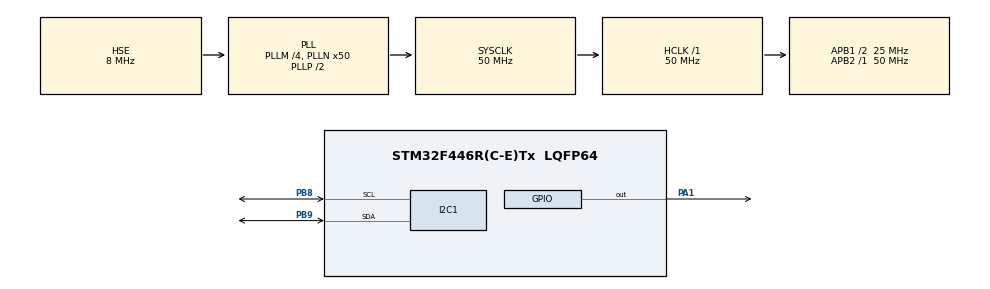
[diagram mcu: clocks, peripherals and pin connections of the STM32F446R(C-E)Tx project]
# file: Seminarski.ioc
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Mcu.Family=STM32F4
Mcu.Name=STM32F446R(C-E)Tx
Mcu.Package=LQFP64
NVIC.PriorityGroup=NVIC_PRIORITYGROUP_4
PA1.Signal=GPIO_Output
PA13.Mode=Serial_Wire
PA13.Signal=SYS_JTMS-SWDIO
PA14.Mode=Serial_Wire
PA14.Signal=SYS_JTCK-SWCLK
PB8.Mode=I2C
PB8.Signal=I2C1_SCL
PB9.Mode=I2C
PB9.Signal=I2C1_SDA
PH0-OSC_IN.Mode=HSE-External-Oscillator
PH0-OSC_IN.Signal=RCC_OSC_IN
PH1-OSC_OUT.Mode=HSE-External-Oscillator
PH1-OSC_OUT.Signal=RCC_OSC_OUT
ProjectManager.HeapSize=0x200
ProjectManager.StackSize=0x400
ProjectManager.TargetToolchain=STM32CubeIDE
RCC.AHBFreq_Value=50000000
RCC.APB1CLKDivider=RCC_HCLK_DIV2
RCC.APB1Freq_Value=25000000
RCC.APB1TimFreq_Value=50000000
RCC.APB2Freq_Value=50000000
RCC.APB2TimFreq_Value=50000000
RCC.CortexFreq_Value=50000000
RCC.HCLKFreq_Value=50000000
RCC.HSE_VALUE=8000000
RCC.PLLM=4
RCC.PLLN=50
RCC.PLLSourceVirtual=RCC_PLLSOURCE_HSE
RCC.SYSCLKFreq_VALUE=50000000
RCC.SYSCLKSource=RCC_SYSCLKSOURCE_PLLCLK
RCC.USBFreq_Value=50000000
RCC.VCOOutputFreq_Value=100000000
TIM6.Period=0xffff-1
TIM6.Prescaler=50-1
VP_TIM6_VS_ClockSourceINT.Mode=Enable_Timer
board=custom

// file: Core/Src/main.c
/* USER CODE BEGIN Header */
/**
  ******************************************************************************
  * @file           : main.c
  * @brief          : Main program body
  ******************************************************************************
  * @attention
  *
  * Copyright (c) 2024 STMicroelectronics.
  * All rights reserved.
  *
  * This software is licensed under terms that can be found in the LICENSE file
  * in the root directory of this software component.
  * If no LICENSE file comes with this software, it is provided AS-IS.
  *
  ******************************************************************************
  */
/* USER CODE END Header */
#include "main.h"
#include "i2c.h"
#include "tim.h"
#include "gpio.h"

/* USER CODE BEGIN Includes */
#include "stdio.h"
/* USER CODE END Includes */

void SystemClock_Config(void);

/* USER CODE BEGIN 0 */
void delay (uint16_t time)
{
	/* change your code here for the delay in microseconds */
	__HAL_TIM_SET_COUNTER(&htim6, 0);
	while ((__HAL_TIM_GET_COUNTER(&htim6))<time);
}

void Display_Temp (float Temp)
{
	char str[20] = {0};
	lcd_put_cur(0, 0);

	sprintf (str, "TEMP: %.2f C", Temp);
	lcd_send_string(str);
	lcd_put_cur(1, 0);
	    if (Temp < 20.0)
	    {
	        lcd_send_string("Obuci se!");
	    }
	    else if (Temp >= 20.0 && Temp <= 30.0)
	    {
	        lcd_send_string("Dobar si!");
	    }
	    else
	    {
	        lcd_send_string("Idi na bazene");
	    }
}

uint8_t Temp_byte1, Temp_byte2;
uint16_t SUM, TEMP;

float Temperature;
uint8_t Presence;

void Set_Pin_Output (GPIO_TypeDef *GPIOx, uint16_t GPIO_Pin)
{
	GPIO_InitTypeDef GPIO_InitStruct = {0};
	GPIO_InitStruct.Pin = GPIO_Pin;
	GPIO_InitStruct.Mode = GPIO_MODE_OUTPUT_PP;
	GPIO_InitStruct.Speed = GPIO_SPEED_FREQ_LOW;
	HAL_GPIO_Init(GPIOx, &GPIO_InitStruct);
}

void Set_Pin_Input (GPIO_TypeDef *GPIOx, uint16_t GPIO_Pin)
{
	GPIO_InitTypeDef GPIO_InitStruct = {0};
	GPIO_InitStruct.Pin = GPIO_Pin;
	GPIO_InitStruct.Mode = GPIO_MODE_INPUT;
	GPIO_InitStruct.Pull = GPIO_PULLUP;
	HAL_GPIO_Init(GPIOx, &GPIO_InitStruct);
}

//DHT11 funkcije
#define DHT11_PORT GPIOA
#define DHT11_PIN GPIO_PIN_1

void DHT11_Start (void)
{
	Set_Pin_Output (DHT11_PORT, DHT11_PIN);  // set the pin as output
	HAL_GPIO_WritePin (DHT11_PORT, DHT11_PIN, 0);   // pull the pin low
	delay (18000);   // wait for 18ms
    HAL_GPIO_WritePin (DHT11_PORT, DHT11_PIN, 1);   // pull the pin high
	delay (20);   // wait for 20us
	Set_Pin_Input(DHT11_PORT, DHT11_PIN);    // set as input
}

uint8_t DHT11_Check_Response (void)
{
	uint8_t Response = 0;
	delay (40);
	if (!(HAL_GPIO_ReadPin (DHT11_PORT, DHT11_PIN)))
	{
		delay (80);
		if ((HAL_GPIO_ReadPin (DHT11_PORT, DHT11_PIN))) Response = 1;
		else Response = -1; // 255
	}
	while ((HAL_GPIO_ReadPin (DHT11_PORT, DHT11_PIN)));   // wait for the pin to go low

	return Response;
}

uint8_t DHT11_Read (void)
{
	uint8_t value = 0;
	    for (int i = 0; i < 8; i++)
	    {
	        while (!(HAL_GPIO_ReadPin(DHT11_PORT, DHT11_PIN)));
	        delay(30);
	        if (HAL_GPIO_ReadPin(DHT11_PORT, DHT11_PIN))
	        {
	            value |= (1 << (7 - i));
	        }
	        while (HAL_GPIO_ReadPin(DHT11_PORT, DHT11_PIN));
	    }
	    return value;
}

/* USER CODE END 0 */

int main(void)
{

  /* MCU Configuration--------------------------------------------------------*/

  /* Reset of all peripherals, Initializes the Flash interface and the Systick. */
  HAL_Init();

  /* Configure the system clock */
  SystemClock_Config();

  /* Initialize all configured peripherals */
  MX_GPIO_Init();
  MX_I2C1_Init();
  MX_TIM6_Init();
  /* USER CODE BEGIN 2 */
  HAL_TIM_Base_Start(&htim6);

  lcd_init();
  lcd_send_string("Ucitavanje >>>");
  HAL_Delay(2000);
  lcd_clear ();

  /* USER CODE END 2 */

  /* Infinite loop */
  while (1)
  {

    /* USER CODE BEGIN 3 */
      Display_Temp(Temperature);

	  DHT11_Start();
	  Presence = DHT11_Check_Response();

	  Temp_byte1 = DHT11_Read ();
	  Temp_byte2 = DHT11_Read ();
	  SUM = DHT11_Read();

	  TEMP = Temp_byte1;

	  Temperature = (float) TEMP;

	  HAL_Delay(1500);

  }
  /* USER CODE END 3 */
}

void SystemClock_Config(void)
{
  RCC_OscInitTypeDef RCC_OscInitStruct = {0};
  RCC_ClkInitTypeDef RCC_ClkInitStruct = {0};

  /** Configure the main internal regulator output voltage
  */
  __HAL_RCC_PWR_CLK_ENABLE();
  __HAL_PWR_VOLTAGESCALING_CONFIG(PWR_REGULATOR_VOLTAGE_SCALE3);

  /** Initializes the RCC Oscillators according to the specified parameters
  * in the RCC_OscInitTypeDef structure.
  */
  RCC_OscInitStruct.OscillatorType = RCC_OSCILLATORTYPE_HSE;
  RCC_OscInitStruct.HSEState = RCC_HSE_ON;
  RCC_OscInitStruct.PLL.PLLState = RCC_PLL_ON;
  RCC_OscInitStruct.PLL.PLLSource = RCC_PLLSOURCE_HSE;
  RCC_OscInitStruct.PLL.PLLM = 4;
  RCC_OscInitStruct.PLL.PLLN = 50;
  RCC_OscInitStruct.PLL.PLLP = RCC_PLLP_DIV2;
  RCC_OscInitStruct.PLL.PLLQ = 2;
  RCC_OscInitStruct.PLL.PLLR = 2;
  if (HAL_RCC_OscConfig(&RCC_OscInitStruct) != HAL_OK)
  {
    Error_Handler();
  }

  /** Initializes the CPU, AHB and APB buses clocks
  */
  RCC_ClkInitStruct.ClockType = RCC_CLOCKTYPE_HCLK|RCC_CLOCKTYPE_SYSCLK
                              |RCC_CLOCKTYPE_PCLK1|RCC_CLOCKTYPE_PCLK2;
  RCC_ClkInitStruct.SYSCLKSource = RCC_SYSCLKSOURCE_PLLCLK;
  RCC_ClkInitStruct.AHBCLKDivider = RCC_SYSCLK_DIV1;
  RCC_ClkInitStruct.APB1CLKDivider = RCC_HCLK_DIV2;
  RCC_ClkInitStruct.APB2CLKDivider = RCC_HCLK_DIV1;

  if (HAL_RCC_ClockConfig(&RCC_ClkInitStruct, FLASH_LATENCY_1) != HAL_OK)
  {
    Error_Handler();
  }
}

void Error_Handler(void)
{
  __disable_irq();
  while (1)
  {
  }
}
